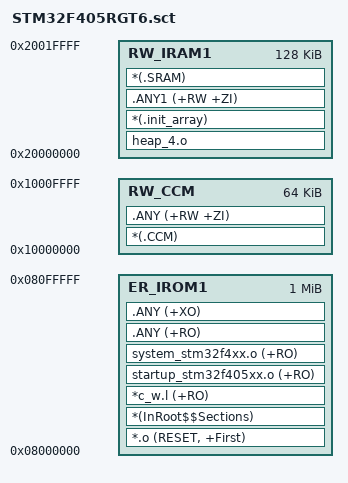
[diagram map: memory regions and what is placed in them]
; *************************************************************
; *** Scatter-Loading Description File generated by uVision ***
; *************************************************************

LR_IROM1 0x08000000 0x00100000  {    ; load region size_region
  ER_IROM1 0x08000000 0x00100000  {  ; load address = execution address
   *.o (RESET, +First)
   *(InRoot$$Sections)
   *c_w.l (+RO)               ;启动文件内用到的库文件，必须放在FLASH
    startup_stm32f405xx.o (+RO)  ;指定生成的startup_stm32f405xx.o的RO放在此区域, 该文件必须放在FLASH
    system_stm32f4xx.o (+RO)     ;指定生成的system_stm32f4xx.o的RO放在此区域, 该文件必须放在FLASH
   .ANY (+RO)
   .ANY (+XO)
  }
  RW_IRAM1 0x20000000 0x00020000  {  ; RW data
    heap_4.o
    *(.init_array)
    .ANY1 (+RW +ZI)
    *(.SRAM)
  }
  RW_CCM 0x10000000 0x00010000  {  ; RW data
   *(.CCM)
   .ANY (+RW +ZI)
  }
}

